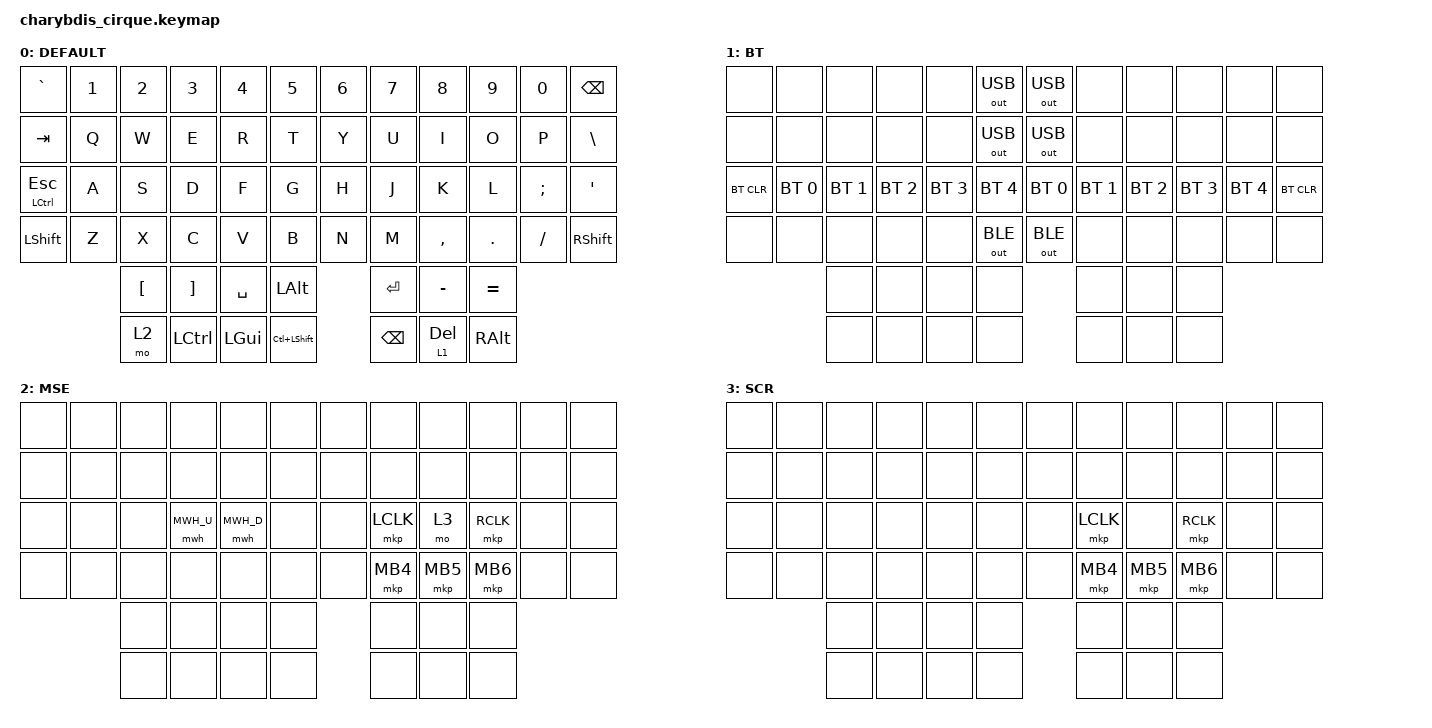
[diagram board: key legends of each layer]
#include <behaviors.dtsi>
#include <dt-bindings/zmk/mouse.h>
#include <dt-bindings/zmk/keys.h>
#include <dt-bindings/zmk/bt.h>
#include <dt-bindings/zmk/outputs.h>

// mouse move settings
#define MMV_U MOVE_VERT(-650)
#define MMV_D MOVE_VERT(650)
#define MMV_L MOVE_HOR(-650)
#define MMV_R MOVE_HOR(650)

&mmv {
        time-to-max-speed-ms = <500>;
        acceleration-exponent=<1>;
};

// mouse wheel settings
#define MWH_U SCROLL_VERT(15)
#define MWH_D SCROLL_VERT(-15)
#define MWH_L SCROLL_HOR(-15)
#define MWH_R SCROLL_HOR(15)

&mwh {
        time-to-max-speed-ms = <2000>;
        acceleration-exponent=<0>;
};

#define DEFAULT 0
#define BT      1
#define MSE     2
#define SCR     3

#define AS(keycode) &as LS(keycode) keycode

/ {
    behaviors {
        td0: tap_dance_0 {
            compatible = "zmk,behavior-tap-dance";
            label = "TAP_DANCE_0";
            #binding-cells = <0>;
            tapping-term-ms = <200>;
            bindings = <&kp ESC>, <&kp TAB>;
        };

        as: auto_shift {
            compatible = "zmk,behavior-hold-tap";
            label = "AUTO_SHIFT";
            #binding-cells = <2>;
            tapping-term-ms = <200>;
            quick-tap-ms = <0>;
            flavor = "tap-preferred";
            bindings = <&kp>, <&kp>;
        };

        modcp: mod_copy {
            compatible = "zmk,behavior-mod-morph";
            label = "MOD_COPY";
            #binding-cells = <0>;
            bindings = <&as LS(C) C>, <&kp C>;
            mods = <(LGUI | RGUI)>;
        };
    };


    macros {
        macro_phone: macro_phone {
            // 1351
            label = "MACRO_PHONE";
            compatible = "zmk,behavior-macro";
            #binding-cells = <0>;
            bindings
                = < &kp N1 &kp N3 &kp N5  &kp N1>
                ;
        };
        macro_email_q: macro_email_q {
            // 2894512440@qq.com
            label = "MACRO_EMAIL_QQ";
            compatible = "zmk,behavior-macro";
            #binding-cells = <0>;
            bindings 
                = < &kp N2 &kp N8 &kp N9 &kp N4 &kp N5 &kp  N1 &kp N2 &kp N4 &kp N4 &kp N0 
                    &kp AT &kp Q &kp Q &kp DOT  &kp C &kp O &kp M>
                ;
        };
        macro_email_g: macro_email_g {
            // 135115
            compatible = "zmk,behavior-macro";
            label = "MACRO_EMAIL_GMAIL";
            #binding-cells = <0>;
            bindings
                = < &kp N1 &kp N3 &kp N5  &kp N1 &kp N1 &kp N5 > ;
        };

    };

//     combos {
//        compatible = "zmk,combos";
//        combo_esc {
//            timeout-ms = <50>;
//            key-positions = <2 38>;
//            bindings = <&kp TAB>;
//        };
//        combo_rgui {
//            timeout-ms = <50>;
//            key-positions = <3 38>;
//            bindings = <&kp CAPS>;
//        };
//
//        combo_LSHFT {
//            timeout-ms = <50>;
//            key-positions = <14 38>;
//            bindings = <&kp  LSHFT>;
//        };
//
//        combo_2 {
//            timeout-ms = <50>;
//            key-positions = <15 38>;
//            bindings = <&kp N2 >;
//        };
//        combo_3 {
//            timeout-ms = <50>;
//            key-positions = <16 38>;
//            bindings = <&kp N3>;
//        };
//        combo_LGUI {
//            timeout-ms = <50>;
//            key-positions = <26 38>;
//            bindings = <&kp LGUI>;
//        };
//        combo_GUI {
//            timeout-ms = <50>;
//            key-positions = <27 38>;
//            bindings = <&tog 1>;
//        };
//        combo_G {
//            timeout-ms = <50>;
//            key-positions = <14 39>;
//            bindings = <&mo 4>;
//        };
//        combo_GU {
//            timeout-ms = <50>;
//            key-positions = <14 39>;
//            bindings = <&mo 2>;
//        };
//        combo_m {
//            timeout-ms = <50>;
//            key-positions = <21 41>;
//            bindings = <&mo 4>;
//        };
//
//   };



    keymap {
       compatible = "zmk,keymap";
       default_layer {
            label = "DEFAULT";
            bindings = <
    &kp GRAVE      &kp N1     &kp N2     &kp N3     &kp N4     &kp N5         &kp N6     &kp N7     &kp N8     &kp N9     &kp N0     &kp BSPC
    &kp TAB        &kp Q      &kp W      &kp E      &kp R      &kp T          &kp Y      &kp U      &kp I      &kp O      &kp P      &kp BSLH
    &mt LCTRL ESC  &kp A      &kp S      &kp D      &kp F      &kp G          &kp H      &kp J      &kp K      &kp L      &kp SEMI    &kp SQT
    &kp LSHIFT     &kp Z      &kp X      &kp C      &kp V      &kp B          &kp N      &kp M      &kp COMMA  &kp DOT    &kp FSLH &kp RSHIFT
                              &kp LBKT   &kp RBKT   &kp SPACE  &kp LALT                  &kp ENTER  &kp MINUS  &kp EQUAL
                              &mo 2      &kp LCTRL  &kp LGUI   &kp LC(LSHIFT)            &kp BSPC   &lt 1 DEL  &kp RALT
             >;
                 trackball-bindings = <&tmv>;
        };


        hotkey_layer {
            label = "BT";
            bindings = <
    &none        &none        &none        &none        &none        &out OUT_USB          &out OUT_USB &none        &none        &none        &none        &none
    &none        &none        &none        &none        &none        &out OUT_USB          &out OUT_USB &none        &none        &none        &none        &none
    &bt BT_CLR   &bt BT_SEL 0 &bt BT_SEL 1 &bt BT_SEL 2 &bt BT_SEL 3 &bt BT_SEL 4          &bt BT_SEL 0 &bt BT_SEL 1 &bt BT_SEL 2 &bt BT_SEL 3 &bt BT_SEL 4 &bt BT_CLR
    &none        &none        &none        &none        &none        &out OUT_BLE          &out OUT_BLE &none        &none        &none        &none        &none
                              &none        &none        &none        &none                              &none        &none        &none
                              &none        &none        &none        &none                              &none        &none        &none
            >;
                 trackball-bindings = <&tsl>;
        };

        mouse_layer {
            label = "MSE";
            bindings = <
    &none        &none        &none        &none        &none        &none                 &none        &none        &none        &none        &none        &none
    &none        &none        &none        &none        &none        &none                 &none        &none        &none        &none        &none        &none
    &none        &none        &none        &mwh MWH_U   &mwh MWH_D   &none                 &none        &mkp LCLK    &mo 3        &mkp RCLK    &none        &none
    &none        &none        &none        &none        &none        &none                 &none        &mkp MB4     &mkp MB5     &mkp MB6     &none        &none
                              &none        &none        &none        &none                              &none        &none        &none
                              &none        &none        &none        &none                              &none        &none        &none
            >;
                trackball-bindings = <&tmv>;
        };

        scroll_layer {
            label = "SCR";
            bindings = <
    &none        &none        &none        &none        &none        &none                 &none        &none        &none        &none        &none        &none
    &none        &none        &none        &none        &none        &none                 &none        &none        &none        &none        &none        &none
    &none        &none        &none        &none        &none        &none                 &none        &mkp LCLK    &none        &mkp RCLK    &none        &none
    &none        &none        &none        &none        &none        &none                 &none        &mkp MB4     &mkp MB5     &mkp MB6     &none        &none
                              &none        &none        &none        &none                              &none        &none        &none
                              &none        &none        &none        &none                              &none        &none        &none
            >;
                trackball-bindings = <&tsl>;
        };


   };
};
